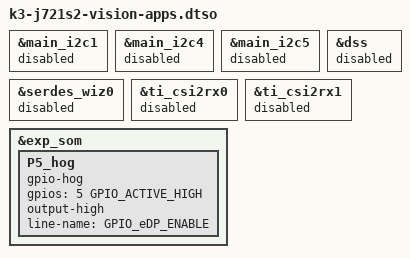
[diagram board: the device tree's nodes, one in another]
// SPDX-License-Identifier: GPL-2.0
/*
 * vision-apps: device-tree overlay
 *
 * Copyright (C) 2019 - 2021 Texas Instruments Incorporated - http://www.ti.com/
 */

/dts-v1/;
/plugin/;

#include "k3-j721s2-rtos-memory-map.dtsi"
#include <dt-bindings/gpio/gpio.h>

&main_i2c1 {
    status = "disabled";
};

&main_i2c4 {
	status = "disabled";
};

&main_i2c5 {
	status = "disabled";
};

&serdes_wiz0 {
    status = "disabled";
};

&dss {
    status = "disabled";
};

&ti_csi2rx0 {
    status = "disabled";
};

&ti_csi2rx1 {
    status = "disabled";
};

&exp_som {
	P5_hog {
		gpio-hog;
		gpios = <5 GPIO_ACTIVE_HIGH>;
		output-high;
		line-name = "GPIO_eDP_ENABLE";
	};
};
